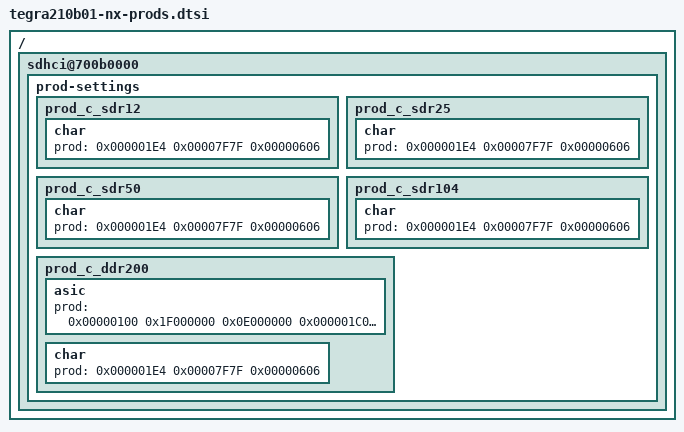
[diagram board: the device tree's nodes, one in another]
/*
 * Copyright (c) 2023, CTCaer <ctcaer@gmail.com>
 *
 * This program is free software; you can redistribute it and/or modify
 * it under the terms of the GNU General Public License as published by
 * the Free Software Foundation; version 2 of the License.
 *
 * This program is distributed in the hope that it will be useful, but WITHOUT
 * ANY WARRANTY; without even the implied warranty of MERCHANTABILITY or
 * FITNESS FOR A PARTICULAR PURPOSE.  See the GNU General Public License for
 * more details.
 *
 */

/ {
	sdhci@700b0000 {
		prod-settings {
			prod_c_sdr12 {
				char {
					prod = <
						0x000001E4 0x00007F7F 0x00000606 // SDMMC_AUTO_CAL_CONFIG_0 	14:8=AUTO_CAL_PD_OFFSET 0x6
										 //				6:0=AUTO_CAL_PU_OFFSET  0x6
						>;
				};
			};
			prod_c_sdr25 {
				char {
					prod = <
						0x000001E4 0x00007F7F 0x00000606 // SDMMC_AUTO_CAL_CONFIG_0 	14:8=AUTO_CAL_PD_OFFSET 0x6
										 //				6:0=AUTO_CAL_PU_OFFSET  0x6
						>;
				};
			};
			prod_c_sdr50 {
				char {
					prod = <
						0x000001E4 0x00007F7F 0x00000606 // SDMMC_AUTO_CAL_CONFIG_0 	14:8=AUTO_CAL_PD_OFFSET 0x6
										 //				6:0=AUTO_CAL_PU_OFFSET  0x6
						>;
				};
			};
			prod_c_sdr104 {
				char {
					prod = <
						0x000001E4 0x00007F7F 0x00000606 // SDMMC_AUTO_CAL_CONFIG_0 	14:8=AUTO_CAL_PD_OFFSET 0x6
										 //				6:0=AUTO_CAL_PU_OFFSET  0x6
						>;
				};
			};
			prod_c_ddr200 {
				asic {
					prod = <0x00000100 0x1F000000 0x0E000000 // SDMMC_VENDOR_CLOCK_CNTRL_0   28:24=TRIM_VAL  0xE
										 //				 23:16=TAP_VAL   manually-tuned
						0x000001C0 0x0000E000 0x00004000 // SDMMC_VENDOR_TUNING_CNTRL0_0 15:13=NUM_TUNING_ITERATIONS 0x2
						0x000001E0 0x0000000F 0x00000000 // SDMMC_SDMEMCOMPPADCTRL_0	 3:0=SDMMC2TMC_CFG_SDMEMCOMP_VREF_SEL 0x0
						0x000001E4 0x30007F7F 0x30000000 // SDMMC_AUTO_CAL_CONFIG_0 	 14:8=AUTO_CAL_PD_OFFSET 0x0
										 //				 6:0=AUTO_CAL_PU_OFFSET  0x0
										 //				 28:28=AUTO_CAL_SLW_OVERRIDE 0x1
										 //				 29:29=AUTO_CAL_ENABLE 0x1
					>;
				};
				char {
					prod = <
						0x000001E4 0x00007F7F 0x00000606 // SDMMC_AUTO_CAL_CONFIG_0 	14:8=AUTO_CAL_PD_OFFSET 0x6
										 //				6:0=AUTO_CAL_PU_OFFSET  0x6
						>;
				};
			};
		};
	};
};
